# AT32F403 register map
Vendor: Keil; Series: AT32F403; File version: 1.0
CPU: CM4 r0p1, little endian, no MPU, FPU, 4 interrupt priority bits
Registers are 32-bit, read-write, reset 0x0 unless marked. A register's access mark holds for its fields unless they carry their own. Offsets are from the block's base; [hi:lo] are bit positions; {n}, {i} and the like mark numbered series; 'fields as' and 'values as' point back to an identical list.

## PWC — Power control
Base 0x40007000
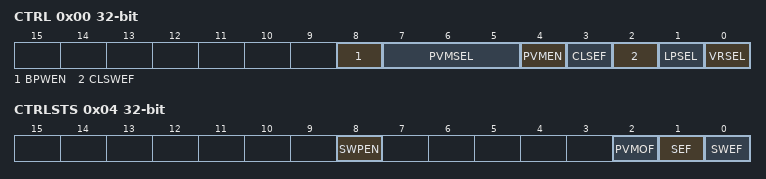
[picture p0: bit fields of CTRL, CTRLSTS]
0x00 CTRL — Power control register (PWC_CTRL)
  [8] BPWEN — Battery powered domain write enable
    0=Disabled (Battery powered domain write disabled); 1=Enabled (Battery powered domain write enabled)
  [7:5] PVMSEL — Power voltage monitoring boundary select
    1=v2_3 (2.3V); 2=v2_4 (2.4V); 3=v2_5 (2.5V); 4=v2_6 (2.6V); 5=v2_7 (2.7V); 6=v2_8 (2.8V); 7=v2_9 (2.9V)
  [4] PVMEN — Power voltage monitoring enable
    0=Disabled (Power voltage monitoring disabled); 1=Enabled (Power voltage monitoring enabled)
  [3] CLSEF wo write-1-clears — Clear SEF flag
    1=Clear the flag
  [2] CLSWEF wo write-1-clears — Clear SWEF flag
    1=Clear the flag
  [1] LPSEL — Low power mode select when Cortex-M4F sleepdeep
    0=Enter deepsleep mode when the CPU enters deepsleep mode; 1=Enter standby mode when the CPU enters deepsleep mode
  [0] VRSEL — Voltage regulator state select when deepsleep mode
    0=Enabled (LDO enabled in deepsleep mode); 1=Disabled (LDO disabled in deepsleep mode)
0x04 CTRLSTS — Power control and status register (PWC_CTRLSTS)
  [8] SWPEN — Standby wake-up pin enable
    0=Disabled; 1=Enabled
  [2] PVMOF ro — Power voltage monitoring output flag
    0=Higher (Power voltage is higher than the threshold); 1=Lower (Power voltage is lower than the threshold)
  [1] SEF ro — Standby mode entry flag
    0=NoStandby (Device is not in standby mode); 1=Standby (Device is in standby mode)
  [0] SWEF ro — Standby wake-up event flag
    0=No wakeup event occurred; 1=Wakeup event occurred

## GPIOA — General purpose IO
Base 0x40010800
Same registers: GPIOB 0x40010C00, GPIOC 0x40011000, GPIOD 0x40011400, GPIOE 0x40011800, GPIOF 0x40011C00, GPIOG 0x40012000
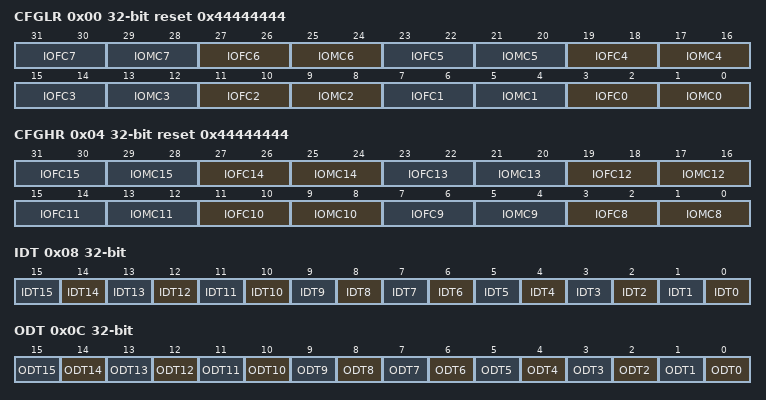
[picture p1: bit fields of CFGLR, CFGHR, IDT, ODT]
0x00 CFGLR reset 0x44444444 — GPIO function configurate register (low/high). **WARNING**: `reset()` writes the hardware reset value which does NOT account for SWD/JTAG pin default configuration. Calling `reset()` may disable debug access to the MCU.
  [4n+3:4n+2] IOFC{n} (n=0..7) — Port n.{n} function configurate bits
    0=Analog input; 1=Floating input; 2=PullDownPullUp (Pull-down or pull-up input); 3=MuxOpenDrain (Multiplexed open drain)
  [4n+1:4n] IOMC{n} (n=0..7) — Port n.{n} mode configurate bits
    0=Input mode; 1=OutputLarge (Output mode, large sourcing/sinking strength); 2=Output mode, normal sourcing/sinking strength; 3=OutputMaximum (Output mode, maximum sourcing/sinking strength)
0x04 CFGHR reset 0x44444444 — GPIO function configurate register (low/high). **WARNING**: `reset()` writes the hardware reset value which does NOT account for SWD/JTAG pin default configuration. Calling `reset()` may disable debug access to the MCU.
  [4n-29:4n-30] IOFC{n} (n=8..15) — Port n.{n} function configurate bits
    values as CFGLR.IOFC0
  [4n-31:4n-32] IOMC{n} (n=8..15) — Port n.{n} mode configurate bits
    values as CFGLR.IOMC0
0x08 IDT ro — Port input data register
  [n] IDT{n} (n=0..15) — Port input data
    0=Low (Input is logic low); 1=High (Input is logic high)
0x0C ODT — Port output data register
  [n] ODT{n} (n=0..15) — Port output data
    on read: 0=PullDown; 1=PullUp | on write: 0=Low (Set output to logic low); 1=High (Set output to logic high)
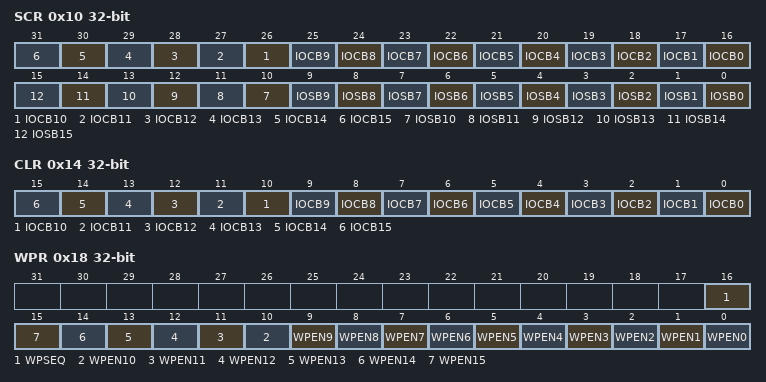
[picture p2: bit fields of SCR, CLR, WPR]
0x10 SCR wo — Port bit set/clear register
  [n+16] IOCB{n} (n=0..15) write-1-clears — Clear bit {n}
    1=Clear the corresponding ODT bit
  [n] IOSB{n} (n=0..15) write-1-sets — Set bit {n}
    1=Set (Set the corresponding ODT bit)
0x14 CLR wo — Port bit reset register
  [n] IOCB{n} (n=0..15) write-1-clears — Clear bit {n}
    1=Clear the corresponding ODT bit
0x18 WPR — Port write protect register
  [16] WPSEQ — Write protect sequence
    0=Clear; 1=Set
  [n] WPEN{n} (n=0..15) — Write protect enable {n}
    on read: 0=NotProtected (Port is not write protected); 1=Protected (Port is write protected) | on write: 0=NoProtect (No effect); 1=Protect (Write protect)
